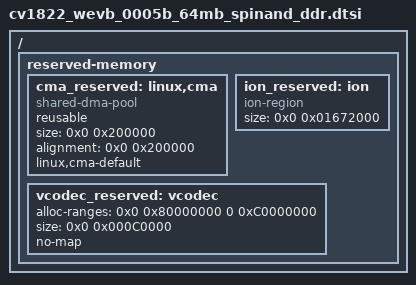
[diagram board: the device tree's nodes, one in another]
/ {

	reserved-memory {
	  #size-cells = <0x2>;
	  #address-cells = <0x2>;
	  ranges;

		cma_reserved: linux,cma {
			compatible = "shared-dma-pool";
			reusable;
			size = <0x0 0x200000>; // 2MB
			alignment = <0x0 0x200000>; // 2MB
			linux,cma-default;
		};

		ion_reserved: ion {
			compatible = "ion-region";
			size = <0x0 0x01672000>; // 22MB
		};

		vcodec_reserved: vcodec {
			alloc-ranges = <0x0 0x80000000 0 0xC0000000>;
			size = <0x0 0x000C0000>; // 768KB
			no-map;
		};
	};
};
